# AT32WB415 register map
Vendor: Keil; Series: AT32WB415; File version: 1.0
CPU: CM4 r0p1, little endian, no MPU, FPU, 4 interrupt priority bits
Registers are 32-bit, read-write, reset 0x0 unless marked. A register's access mark holds for its fields unless they carry their own. Offsets are from the block's base; [hi:lo] are bit positions; {n}, {i} and the like mark numbered series.

## EXINT
Base 0x40010400
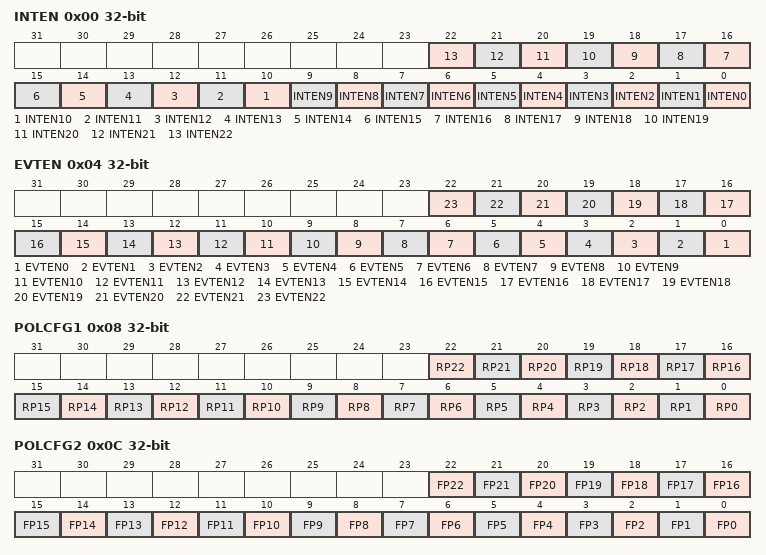
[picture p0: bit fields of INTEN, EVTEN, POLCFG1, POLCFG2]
0x00 INTEN — Interrupt enable register
  [n] INTEN{n} (n=0..22) — Interrupt enable or disable on line {n}
    on read: 0=Disabled (Interrupt request is disabled); 1=Enabled (Interrupt request is enabled) | on write: 0=Disable (Interrupt request disable); 1=Enable (Interrupt request enable)
0x04 EVTEN — Event enable register
  [n] EVTEN{n} (n=0..22) — Event enable or disable on line {n}
    on read: 0=Disabled (Event request is disabled); 1=Enabled (Event request is enabled) | on write: 0=Disable (Event request disable); 1=Enable (Event request enable)
0x08 POLCFG1 — Rising polarity configuration register
  [n] RP{n} (n=0..22) — Rising polarity configuration bit on line {n}
    on read: 0=Disabled (Rising trigger is disabled); 1=Enabled (Rising trigger is enabled) | on write: 0=Disable (Rising trigger disable); 1=Enable (Rising trigger enable)
0x0C POLCFG2 — Falling polarity configuration register
  [n] FP{n} (n=0..22) — Falling polarity configuration bit on line {n}
    on read: 0=Disabled (Falling polarity is disabled); 1=Enabled (Falling polarity is enabled) | on write: 0=Disable (Falling polarity disable); 1=Enable (Falling polarity enable)
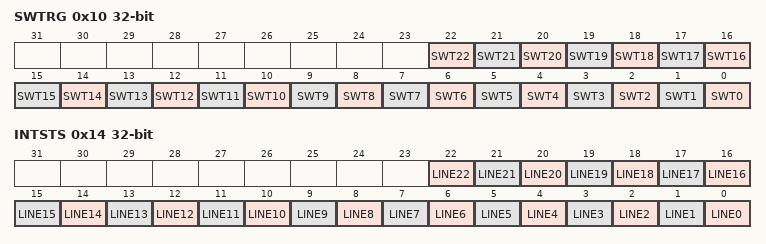
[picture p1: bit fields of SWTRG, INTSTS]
0x10 SWTRG — Software triggle register
  [n] SWT{n} (n=0..22) write-1-sets — Software trigger on line {n}
    on read: 0=NoTrigger (Default value); 1=Triggered (Software trigger generated) | on write: 1=Trigger (Generate trigger)
0x14 INTSTS — Interrupt status register
  [n] LINE{n} (n=0..22) write-1-clears — Line {n} status bit
    on read: 0=No interrupt occurred; 1=Interrupt occurred | on write: 1=Clear status flag

## WDT — Watchdog
Base 0x40003000
0x00 CMD — Command register
  [15:0] CMD
    0x5555=Unlock write-protected WDT_DIV and WDT_RLD; 0xAAAA=Reload counter; 0xCCCC=Enable WDT. If the hardware watchdog has been enabled, ignore this operation.
0x04 DIV — Division register
  [2:0] DIV — Division divider
    0=LICK divided by 4; 1=LICK divided by 8; 2=LICK divided by 16; 3=LICK divided by 32; 4=LICK divided by 64; 5=LICK divided by 128; 6=LICK divided by 256; 7=div256_2 (LICK divided by 256)
0x08 RLD reset 0xFFF — Reload register
  [11:0] RLD — Reload value
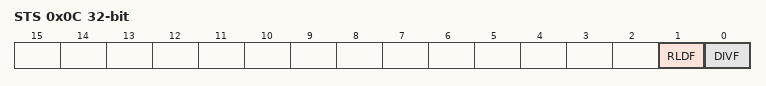
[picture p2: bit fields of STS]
0x0C STS ro — Status register
  [1] RLDF — Reload value update complete flag
    0=Complete (Reload value update complete); 1=InProgress (Reload value update is in process)
  [0] DIVF — Division value update complete flag
    0=Complete (Division value update complete); 1=InProgress (Division value update is in process)

## WWDT — Window watchdog
Base 0x40002C00
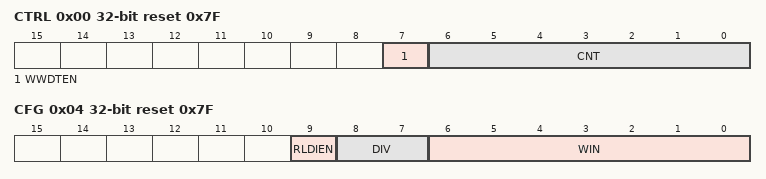
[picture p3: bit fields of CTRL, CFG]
0x00 CTRL reset 0x7F — Control register
  [7] WWDTEN write-1-sets — Window watchdog enable
    on read: 0=Disabled; 1=Enabled | on write: 1=Enable
  [6:0] CNT — Decrement counter
0x04 CFG reset 0x7F — Configuration register
  [9] RLDIEN — Reload counter interrupt
    on read: 0=Disabled; 1=Enabled | on write: 0=Disable; 1=Enable
  [8:7] DIV — Clock division value
    0=PCLK1 divided by 4096; 1=PCLK1 divided by 8192; 2=PCLK1 divided by 16384; 3=PCLK1 divided by 32768
  [6:0] WIN — Window value
0x08 STS — Status register
  [0] RLDF write-0-clears — Reload counter interrupt flag
    on read: 0=NotReached (Downcounter doesn't reached 0x40); 1=Reached (Downcounter reached 0x40) | on write: 0=Clear flag

## CMP — Comparator
Base 0x40002400
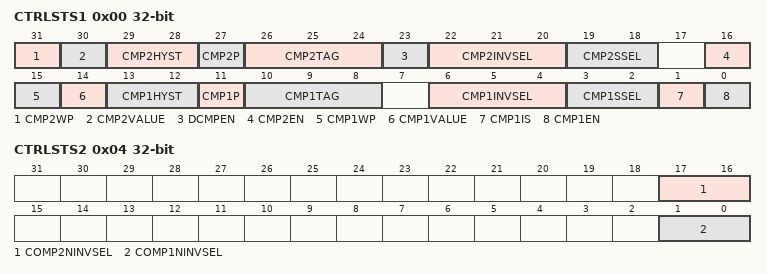
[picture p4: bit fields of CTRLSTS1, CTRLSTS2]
0x00 CTRLSTS1 — CMP control/status register1
  [31] CMP2WP — Comparator2 write protect
  [30] CMP2VALUE ro — Comparator2 output value
  [29:28] CMP2HYST — Comparator2 hysteresis
  [27] CMP2P — Comparator2 polarity
  [26:24] CMP2TAG — Comparator2 output target
  [23] DCMPEN — Double comparator mode enable
  [22:20] CMP2INVSEL — Comparator2 inverting selection
  [19:18] CMP2SSEL — Comparator2 speed selection
  [16] CMP2EN — Comparator2 enable bit
  [15] CMP1WP — Comparator1 write protect
  [14] CMP1VALUE ro — Comparator1 output value
  [13:12] CMP1HYST — Comparator1 hysteresis
  [11] CMP1P — Comparator1 polarity
  [10:8] CMP1TAG — Comparator1 output target
  [6:4] CMP1INVSEL — Comparator1 inverting selection
  [3:2] CMP1SSEL — Comparator1 speed selection
  [1] CMP1IS — Comparator1 input shift
  [0] CMP1EN — Comparator1 enable bit
0x04 CTRLSTS2 — CMP control/status register2
  [17:16] COMP2NINVSEL — Comparator2 non-inverting input selection
  [1:0] COMP1NINVSEL — Comparator1 non-inverting input selection
